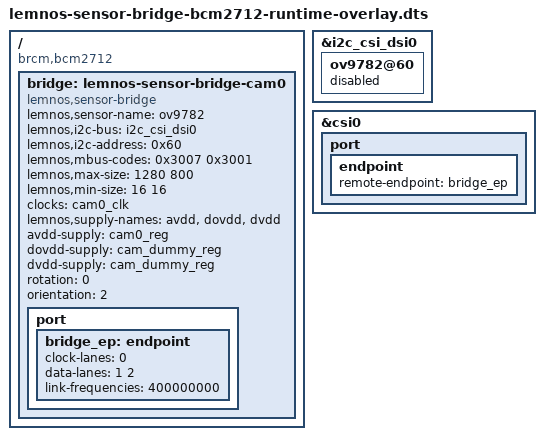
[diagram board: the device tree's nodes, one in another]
// SPDX-License-Identifier: GPL-2.0-only
// Lemnos sensor bridge on the BCM2712 camera port, applied at runtime.
//
// Unlike lemnos-sensor-bridge-bcm2712-overlay.dts (a boot overlay used in place of
// ov9782-overlay), this one goes on top of the live device tree of a BCM2712
// image that booted with `dtoverlay=ov9782,cam0,clk-continuous`, through
// configfs (/sys/kernel/config/device-tree/overlays/). Removing it restores
// the original tree. It is fixed to that wiring: no parameters, because the
// kernel's configfs interface does not process __overrides__.
//
// What it changes:
//   1. i2c_csi_dsi0 (i2c@88000, /dev/i2c-10) ov9782@60: status = "disabled".
//      The i2c core unregisters the 10-0060 client, which frees address 0x60
//      for i2c-dev (I2C_SLAVE fails with EBUSY while any client exists there).
//   2. Adds /lemnos-sensor-bridge-cam0 (platform device, lemnos_sensor_bridge.ko)
//      with the ov9782 node's supplies, clock, lanes and link frequency.
//   3. csi0 (rp1-cfe, csi@110000) port/endpoint: remote-endpoint -> bridge.
//      rp1-cfe must be unbound while this is applied and rebound after.
//
// The bridge endpoint has no remote-endpoint back to csi0. Nothing reads it
// (rp1-cfe follows its own endpoint to the bridge node; the bridge only parses
// lanes and link frequencies), and with it fw_devlink would make the new bridge
// device a consumer of the (then unbound) csi0 device and defer its probe until
// rp1-cfe binds. Without it no phandle from the live tree is hard-coded here.
//
// Build: dtc -@ -I dts -O dtb -o lemnos-sensor-bridge-bcm2712-runtime.dtbo <this file>
/dts-v1/;
/plugin/;

/ {
	compatible = "brcm,bcm2712";

	/* 1. Take the sensor's I2C client away from the ov9282 driver. */
	fragment@0 {
		target = <&i2c_csi_dsi0>;
		__overlay__ {
			ov9782@60 {
				status = "disabled";
			};
		};
	};

	/* 2. The bridge, standing in for the sensor driver. */
	fragment@1 {
		target-path = "/";
		__overlay__ {
			bridge: lemnos-sensor-bridge-cam0 {
				compatible = "lemnos,sensor-bridge";
				status = "okay";

				lemnos,sensor-name = "ov9782";
				lemnos,i2c-bus = <&i2c_csi_dsi0>;
				lemnos,i2c-address = <0x60>;

				/* MEDIA_BUS_FMT_SBGGR10_1X10, MEDIA_BUS_FMT_SBGGR8_1X8 */
				lemnos,mbus-codes = <0x3007 0x3001>;
				lemnos,max-size = <1280 800>;
				lemnos,min-size = <16 16>;

				/* Enabled together through LEMNOS_CID_POWER. */
				clocks = <&cam0_clk>;
				lemnos,supply-names = "avdd", "dovdd", "dvdd";
				avdd-supply = <&cam0_reg>;
				dovdd-supply = <&cam_dummy_reg>;
				dvdd-supply = <&cam_dummy_reg>;

				rotation = <0>;
				orientation = <2>;

				port {
					bridge_ep: endpoint {
						/* No remote-endpoint: see above. */
						clock-lanes = <0>;
						data-lanes = <1 2>;
						/* Continuous clock, as booted (clk-continuous). */
						link-frequencies = /bits/ 64 <400000000>;
					};
				};
			};
		};
	};

	/* 3. Point the receiver at the bridge. No labels here: a merged node
	 * that carries a phandle would make the kernel reject the overlay. */
	fragment@2 {
		target = <&csi0>;
		__overlay__ {
			port {
				endpoint {
					remote-endpoint = <&bridge_ep>;
				};
			};
		};
	};
};
